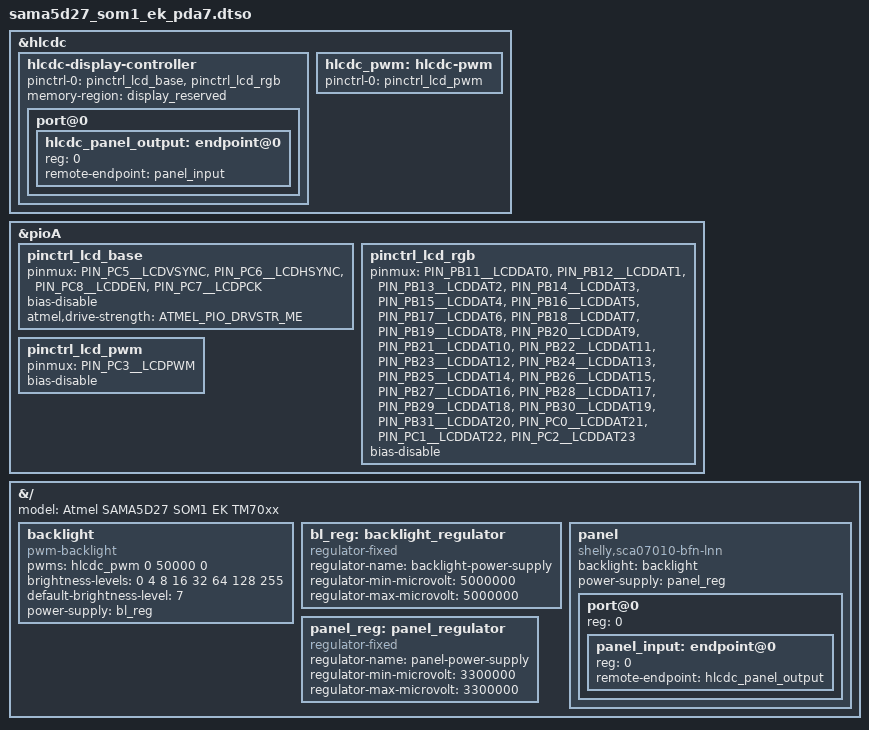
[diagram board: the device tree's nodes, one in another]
// SPDX-License-Identifier: (GPL-2.0+ OR MIT)
/*
 * sama5d27_som1_ek_pda7.dtso - Device Tree file for SAMA5D27 SOM1 EK board
 * overlay blob for PDA7000 LCD.
 *
 * Copyright (C) 2018 Microchip Technology, Inc.
 * Author: Codrin Ciubotariu <codrin.ciubotariu@microchip.com>
 *
 */
/dts-v1/;
/plugin/;

#include "sama5d2-pinfunc.h"
#include "dt-bindings/pinctrl/at91.h"


&hlcdc {
	status = "okay";

	

	hlcdc-display-controller {
		pinctrl-names = "default";
		pinctrl-0 = <&pinctrl_lcd_base &pinctrl_lcd_rgb>;
		memory-region = <&display_reserved>;
		port@0 {
			#address-cells = <1>;
			#size-cells = <0>;

			hlcdc_panel_output: endpoint@0 {
				reg = <0>;
				remote-endpoint = <&panel_input>;
			};
		};
	};

	hlcdc_pwm: hlcdc-pwm {
		pinctrl-names = "default";
		pinctrl-0 = <&pinctrl_lcd_pwm>;
	};
};


&pioA {

	pinctrl_lcd_base: pinctrl_lcd_base {
		pinmux = <PIN_PC5__LCDVSYNC>,
			 <PIN_PC6__LCDHSYNC>,
			 <PIN_PC8__LCDDEN>,
			 <PIN_PC7__LCDPCK>;
		bias-disable;
		atmel,drive-strength = <ATMEL_PIO_DRVSTR_ME>;
	};

	pinctrl_lcd_rgb: pinctrl_lcd_rgb {
		pinmux = <PIN_PB11__LCDDAT0>,
			 <PIN_PB12__LCDDAT1>,
			 <PIN_PB13__LCDDAT2>,
			 <PIN_PB14__LCDDAT3>,
			 <PIN_PB15__LCDDAT4>,
			 <PIN_PB16__LCDDAT5>,
			 <PIN_PB17__LCDDAT6>,
			 <PIN_PB18__LCDDAT7>,
			 <PIN_PB19__LCDDAT8>,
			 <PIN_PB20__LCDDAT9>,
			 <PIN_PB21__LCDDAT10>,
			 <PIN_PB22__LCDDAT11>,
			 <PIN_PB23__LCDDAT12>,
			 <PIN_PB24__LCDDAT13>,
			 <PIN_PB25__LCDDAT14>,
			 <PIN_PB26__LCDDAT15>,
			 <PIN_PB27__LCDDAT16>,
			 <PIN_PB28__LCDDAT17>,
			 <PIN_PB29__LCDDAT18>,
			 <PIN_PB30__LCDDAT19>,
			 <PIN_PB31__LCDDAT20>,
			 <PIN_PC0__LCDDAT21>,
			 <PIN_PC1__LCDDAT22>,
			 <PIN_PC2__LCDDAT23>;
		bias-disable;
	};

	pinctrl_lcd_pwm: pinctrl_lcd_pwm {
		pinmux = <PIN_PC3__LCDPWM>;
		bias-disable;
	};
};

&{/} {
	model = "Atmel SAMA5D27 SOM1 EK TM70xx";
	backlight: backlight {
		compatible = "pwm-backlight";
		pwms = <&hlcdc_pwm 0 50000 0>;
		brightness-levels = <0 4 8 16 32 64 128 255>;
		default-brightness-level = <7>;
		power-supply = <&bl_reg>;
		status = "okay";
	};

	bl_reg: backlight_regulator {
		compatible = "regulator-fixed";
		regulator-name = "backlight-power-supply";
		regulator-min-microvolt = <5000000>;
		regulator-max-microvolt = <5000000>;
		status = "okay";
	};

	panel: panel {
		compatible = "shelly,sca07010-bfn-lnn", "simple-panel";
		backlight = <&backlight>;
		power-supply = <&panel_reg>;
		#address-cells = <1>;
		#size-cells = <0>;
		status = "okay";

		port@0 {
			reg = <0>;
			#address-cells = <1>;
			#size-cells = <0>;

			panel_input: endpoint@0 {
				reg = <0>;
				remote-endpoint = <&hlcdc_panel_output>;
			};
		};
	};

	panel_reg: panel_regulator {
		compatible = "regulator-fixed";
		regulator-name = "panel-power-supply";
		regulator-min-microvolt = <3300000>;
		regulator-max-microvolt = <3300000>;
		status = "okay";
	};
};
